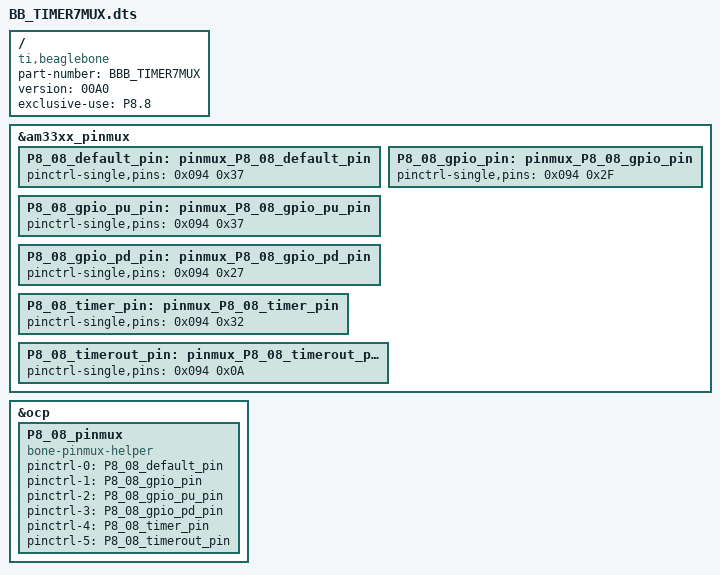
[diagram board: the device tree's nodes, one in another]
/*
 * Setup to conrol pinmux for timer7 pin (P8.8)
 * This is based on a single-pin lift from cape-universal
 */
/dts-v1/;
/plugin/;

/ {
	compatible = "ti,beaglebone", "ti,beaglebone-black", "ti,beaglebone-green";

        /* identification */
        part-number = "BBB_TIMER7MUX";
        version = "00A0";

        /* state the resources this cape uses */
        exclusive-use =
                /* the pin header uses */
                "P8.8";         /* timer7 pin */

        fragment@0 {
                target = <&am33xx_pinmux>;
                __overlay__ {

			/* P8_08 (ZCZ ball T7 ) */
			P8_08_default_pin: pinmux_P8_08_default_pin {
			pinctrl-single,pins = <0x094  0x37>; };     /* Mode 7, Pull-Up, RxActive */
			P8_08_gpio_pin: pinmux_P8_08_gpio_pin {
			pinctrl-single,pins = <0x094  0x2F>; };     /* Mode 7, RxActive */
			P8_08_gpio_pu_pin: pinmux_P8_08_gpio_pu_pin {
			pinctrl-single,pins = <0x094  0x37>; };     /* Mode 7, Pull-Up, RxActive */
			P8_08_gpio_pd_pin: pinmux_P8_08_gpio_pd_pin {
			pinctrl-single,pins = <0x094  0x27>; };     /* Mode 7, Pull-Down, RxActive */
			P8_08_timer_pin: pinmux_P8_08_timer_pin {
			pinctrl-single,pins = <0x094  0x32>; };     /* Mode 2, Pull-Up, RxActive */
			P8_08_timerout_pin: pinmux_P8_08_timerout_pin {
			pinctrl-single,pins = <0x094  0x0A>; };     /* Mode 2 */
                };
        };

	fragment@1 {
		target = <&ocp>;
		__overlay__ {

			P8_08_pinmux {
				compatible = "bone-pinmux-helper";
				status = "okay";
				pinctrl-names = "default", "gpio", "gpio_pu", "gpio_pd", "timer", "timerout";
				pinctrl-0 = <&P8_08_default_pin>;
				pinctrl-1 = <&P8_08_gpio_pin>;
				pinctrl-2 = <&P8_08_gpio_pu_pin>;
				pinctrl-3 = <&P8_08_gpio_pd_pin>;
				pinctrl-4 = <&P8_08_timer_pin>;
				pinctrl-5 = <&P8_08_timerout_pin>;
			};
		};
	};
};
